# DMA register map
Vendor: Texas Instruments
Peripheral module from a debugger description file (folder CC27xxx7).
Registers are 32-bit, access per field, reset 0x0 unless marked. A register's access mark holds for its fields unless they carry their own. Offsets are as the file gives them; lines under a group give offsets from that group; [hi:lo] are bit positions; {n}, {i} and the like mark numbered series; 'fields as' and 'values as' point back to an identical list; <NAME> marks a mode.

## DMA — ARM Micro Direct Memory Access Controller
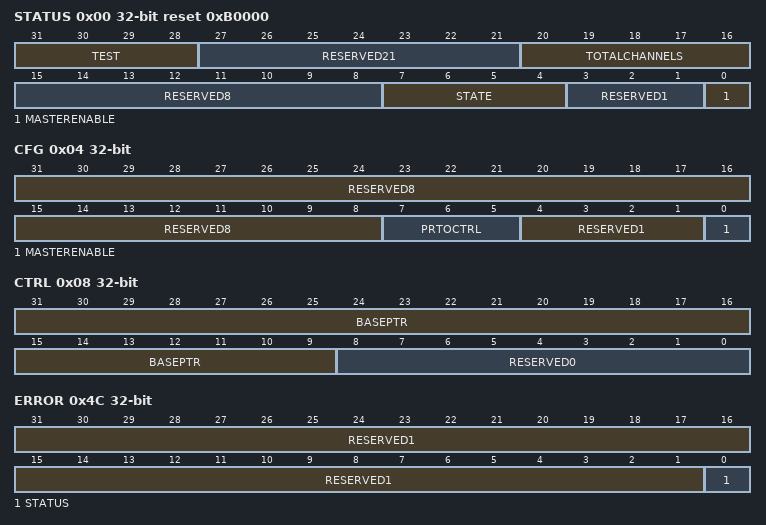
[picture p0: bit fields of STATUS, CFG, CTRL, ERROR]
0x00 STATUS ro reset 0xB0000
  [31:28] TEST — 0x0: Controller does not include the integration test logic 0x1: Controller includes the integration test logic 0x2: Undefined ... 0xF: Undefined
  [27:21] RESERVED21 — Reads to this field return zero, writes to this field are ignored.
  [20:16] TOTALCHANNELS — Register value returns number of available uDMA channels minus one. For example a read out value of: 0x00: Show that the controller is configured to use 1 uDMA channel 0x01: Shows that the controller is configured to use 2 uDMA channels ... 0x1F: Shows that the controller is configured to use 32 uDMA channels (32-1=31=0x1F)
  [15:8] RESERVED8 — Reads to this field return zero, writes to this field are ignored.
  [7:4] STATE — Current state of the control state machine. State can be one of the following: 0x0: Idle 0x1: Reading channel controller data 0x2: Reading source data end pointer 0x3: Reading destination data end pointer 0x4: Reading source data 0x5: Writing destination data 0x6: Waiting for uDMA request to clear 0x7: Writing channel controller data 0x8: Stalled 0x9: Done 0xA: Peripheral scatter-gather transition 0xB: Undefined ... 0xF: Undefined.
  [3:1] RESERVED1 — Reads to this field return zero, writes to this field are ignored.
  [0] MASTERENABLE — Shows the enable status of the controller as configured by CFG.MASTERENABLE:
    1=EN (Controller is enabled); 0=DIS (Controller is disabled)
0x04 CFG wo — Configuration Register.
  [31:8] RESERVED8 — Reads to this field return zero, writes to this field are ignored.
  [7:5] PRTOCTRL — Sets the AHB-Lite bus protocol protection state by controlling the AHB signal HProt[3:1] as follows: Bit [7] Controls HProt[3] to indicate if a cacheable access is occurring. Bit [6] Controls HProt[2] to indicate if a bufferable access is occurring. Bit [5] Controls HProt[1] to indicate if a privileged access is occurring. When bit [n] = 1 then the corresponding HProt bit is high. When bit [n] = 0 then the corresponding HProt bit is low. This field controls HProt[3:1] signal for all transactions initiated by uDMA except two transactions below: - the read from the address indicated by source address pointer - the write to the address indicated by destination address pointer HProt[3:1] for these two exceptions can be controlled by dedicated fields in the channel configutation descriptor.
  [4:1] RESERVED1 — Reads to this field return zero, writes to this field are ignored.
  [0] MASTERENABLE — Enables the controller.
    1=EN (Enables the controller); 0=DIS (Disables the controller)
0x08 CTRL — Channel Control Data Base Pointer Register.
  [31:9] BASEPTR rw — This register point to the base address for the primary data structures of each DMA channel. This is not stored in module, but in system memory, thus space must be allocated for this usage when DMA is in usage
  [8:0] RESERVED0 ro — Reads to this field return zero, writes to this field are ignored.
0x0C ALTCTRL ro reset 0x100 — Channel Alternate Control Data Base Pointer Register.
  [31:0] BASEPTR — This register shows the base address for the alternate data structures and is calculated by module, thus read only
0x10 WAITONREQ ro reset 0xFFF — Channel Wait On Request Status Register.
  [11:0] CHNLSTATUS — Channel wait on request status: Bit [Ch] = 0: Once uDMA receives a single or burst request on channel Ch, this channel may come out of active state even if request is still present. Bit [Ch] = 1: Once uDMA receives a single or burst request on channel Ch, it keeps channel Ch in active state until the requests are deasserted. This handshake is necessary for channels where the requester is in an asynchronous domain or can run at slower clock speed than uDMA
0x14 SOFTREQ — Channel Software Request Register.
  [11:0] CHNLS wo — Set the appropriate bit to generate a software uDMA request on the corresponding uDMA channel Bit [Ch] = 0: Does not create a uDMA request for channel Ch Bit [Ch] = 1: Creates a uDMA request for channel Ch Writing to a bit where a uDMA channel is not implemented does not create a uDMA request for that channel
0x18 SETBURST — Channel Set UseBurst Register.
  [11:0] CHNLS rw — Returns the useburst status, or disables individual channels from generating single uDMA requests. The value R is the arbitration rate and stored in the controller data structure. Read as: Bit [Ch] = 0: uDMA channel Ch responds to both burst and single requests on channel Ch. The controller performs 2^R, or single, bus transfers. Bit [Ch] = 1: uDMA channel Ch does not respond to single transfer requests. The controller only responds to burst transfer requests and performs 2^R transfers. Write as: Bit [Ch] = 0: No effect. Use the CLEARBURST.CHNLS to set bit [Ch] to 0. Bit [Ch] = 1: Disables single transfer requests on channel Ch. The controller performs 2^R transfers for burst requests. Writing to a bit where a uDMA channel is not implemented has no effect
0x1C CLEARBURST — Channel Clear UseBurst Register.
  [11:0] CHNLS wo — Set the appropriate bit to enable single transfer requests. Write as: Bit [Ch] = 0: No effect. Use the SETBURST.CHNLS to disable single transfer requests. Bit [Ch] = 1: Enables single transfer requests on channel Ch. Writing to a bit where a uDMA channel is not implemented has no effect.
0x20 SETREQMASK — Channel Set Request Mask Register.
  [11:0] CHNLS rw — Returns the burst and single request mask status, or disables the corresponding channel from generating uDMA requests. Read as: Bit [Ch] = 0: External requests are enabled for channel Ch. Bit [Ch] = 1: External requests are disabled for channel Ch. Write as: Bit [Ch] = 0: No effect. Use the CLEARREQMASK.CHNLS to enable uDMA requests. Bit [Ch] = 1: Disables uDMA burst request channel [Ch] and uDMA single request channel [Ch] input from generating uDMA requests. Writing to a bit where a uDMA channel is not implemented has no effect
0x24 CLEARREQMASK — Clear Channel Request Mask Register.
  [11:0] CHNLS wo — Set the appropriate bit to enable uDMA request for the channel. Write as: Bit [Ch] = 0: No effect. Use the SETREQMASK.CHNLS to disable channel Ch from generating requests. Bit [Ch] = 1: Enables channel [Ch] to generate uDMA requests. Writing to a bit where a uDMA channel is not implemented has no effect.
0x28 SETCHANNELEN — Set Channel Enable Register.
  [11:0] CHNLS rw — Returns the enable status of the channels, or enable the corresponding channels. Read as: Bit [Ch] = 0: Channel Ch is disabled. Bit [Ch] = 1: Channel Ch is enabled. Write as: Bit [Ch] = 0: No effect. Use the CLEARCHANNELEN.CHNLS to disable a channel Bit [Ch] = 1: Enables channel Ch Writing to a bit where a uDMA channel is not implemented has no effect
0x2C CLEARCHANNELEN — Clear Channel Enable Register.
  [11:0] CHNLS wo — Set the appropriate bit to disable the corresponding uDMA channel. Write as: Bit [Ch] = 0: No effect. Use the SETCHANNELEN.CHNLS to enable uDMA channels. Bit [Ch] = 1: Disables channel Ch Writing to a bit where a uDMA channel is not implemented has no effect
0x30 SETCHNLPRIALT — Channel Set Primary-Alternate Register.
  [11:0] CHNLS rw — Returns the channel control data structure status, or selects the alternate data structure for the corresponding uDMA channel. Read as: Bit [Ch] = 0: uDMA channel Ch is using the primary data structure. Bit [Ch] = 1: uDMA channel Ch is using the alternate data structure. Write as: Bit [Ch] = 0: No effect. Use the CLEARCHNLPRIALT.CHNLS to disable a channel Bit [Ch] = 1: Selects the alternate data structure for channel Ch Writing to a bit where a uDMA channel is not implemented has no effect
0x34 CLEARCHNLPRIALT — Channel Clear Primary-Alternate Register.
  [11:0] CHNLS wo — Clears the appropriate bit to select the primary data structure for the corresponding uDMA channel. Write as: Bit [Ch] = 0: No effect. Use the SETCHNLPRIALT.CHNLS to select the alternate data structure. Bit [Ch] = 1: Selects the primary data structure for channel Ch. Writing to a bit where a uDMA channel is not implemented has no effect
0x38 SETCHNLPRIORITY — Set Channel Priority Register.
  [11:0] CHNLS rw — Returns the channel priority mask status, or sets the channel priority to high. Read as: Bit [Ch] = 0: uDMA channel Ch is using the default priority level. Bit [Ch] = 1: uDMA channel Ch is using a high priority level. Write as: Bit [Ch] = 0: No effect. Use the CLEARCHNLPRIORITY.CHNLS to set channel Ch to the default priority level. Bit [Ch] = 1: Channel Ch uses the high priority level. Writing to a bit where a uDMA channel is not implemented has no effect
0x3C CLEARCHNLPRIORITY — Clear Channel Priority Register.
  [11:0] CHNLS wo — Clear the appropriate bit to select the default priority level for the specified uDMA channel. Write as: Bit [Ch] = 0: No effect. Use the SETCHNLPRIORITY.CHNLS to set channel Ch to the high priority level. Bit [Ch] = 1: Channel Ch uses the default priority level. Writing to a bit where a uDMA channel is not implemented has no effect
0x4C ERROR — Error Status and Clear Register.
  [31:1] RESERVED1 ro — Reads to this field return zero, writes to this field are ignored.
  [0] STATUS rw — Returns the status of bus error flag in uDMA, or clears this bit Read as: 0: No bus error detected 1: Bus error detected Write as: 0: No effect, status of bus error flag is unchanged. 1: Clears the bus error flag.
0x504 REQDONE — Channel Request Done Register.
  [11:0] CHNLS rw — Reflects the uDMA done status for the given channel, channel [Ch]. It's a sticky done bit. Unless cleared by writing a 1, it holds the value of 1. Read as: Bit [Ch] = 0: Request has not completed for channel Ch Bit [Ch] = 1: Request has completed for the channel Ch Writing a 1 to individual bits would clear the corresponding bit. Write as: Bit [Ch] = 0: No effect. Bit [Ch] = 1: The corresponding [Ch] bit is cleared and is set to 0
0x520 DONEMASK — Channel Request Done Mask Register.
  [11:0] CHNLS rw — Controls the propagation of the uDMA done and active state to the assigned peripheral. Specifically used for software channels. Read as: Bit [Ch] = 0: uDMA done and active state for channel Ch is not blocked from reaching to the peripherals. Note that the uDMA done state for channel [Ch] is blocked from contributing to generation of combined uDMA done signal Bit [Ch] = 1: uDMA done and active state for channel Ch is blocked from reaching to the peripherals. Note that the uDMA done state for channel [Ch] is not blocked from contributing to generation of combined uDMA done signal Write as: Bit [Ch] = 0: Allows uDMA done and active state to propagate to the peripherals. Note that this disables uDMA done state for channel [Ch] from contributing to generation of combined uDMA done signal Bit [Ch] = 1: Blocks uDMA done and active state to propagate to the peripherals. Note that this enables uDMA done for channel [Ch] to contribute to generation of combined uDMA done signal.
